# R7FA8M1AH register map
Vendor: Renesas; Series: RA8; File version: 1.2
CPU: CM85 r0p0, little endian, MPU, FPU, VTOR, 4 interrupt priority bits
Registers are 32-bit, read-write, reset 0x0 unless marked. A register's access mark holds for its fields unless they carry their own. Offsets are from the block's base; [hi:lo] are bit positions.

## FACI — Flash Application Command Interface
Base 0x4011E000
Same registers: FACI_NS 0x5011E000
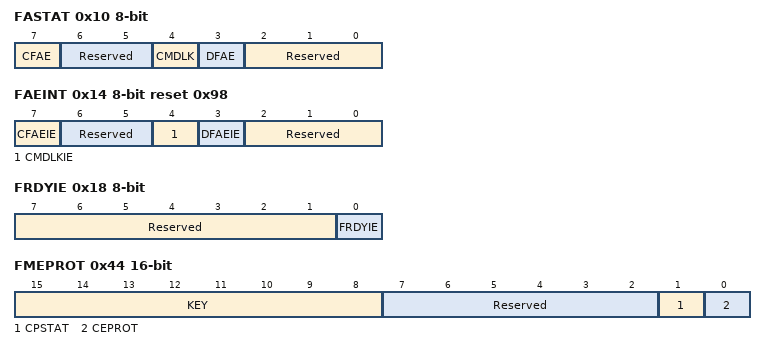
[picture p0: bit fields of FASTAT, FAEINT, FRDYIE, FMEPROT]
0x10 FASTAT 8-bit — Flash Access Status Register
  [7] CFAE write-0-clears read-modifies — Code Flash Access Error
    0=No code flash access error has occurred; 1=Code flash access error has occurred
  [6:5] Reserved — These bits are read as 00. The write value should be 00.
  [4] CMDLK ro — Command Lock
    0=Flash sequencer is not in "Command Lock" state; 1=Flash sequencer is in "Command Lock" state
  [3] DFAE write-0-clears read-modifies — Data Flash Access Error
    0=No data flash access error has occurred; 1=Data flash access error has occurred
  [2:0] Reserved — These bits are read as 000. The write value should be 000.
0x14 FAEINT 8-bit reset 0x98 — Flash Access Error Interrupt Enable Register
  [7] CFAEIE — Code Flash Access Error Interrupt Enable
    0=Does not generate "intflerr" interrupt request when CFAE = "1"; 1=Generates "intflerr" interrupt request when CFAE = "1"
  [6:5] Reserved — These bits are read as 00. The write value should be 00.
  [4] CMDLKIE — Command Lock Interrupt Enable
    0=Does not generate "intflerr" interrupt request when CMDLK = "1"; 1=Generates "intflerr" interrupt request when CMDLK = "1"
  [3] DFAEIE — Data Flash Access Error Interrupt Enable
    0=Does not generate "intflerr" interrupt request when DFAE = "1"; 1=Generates "intflerr" interrupt request when DFAE = "1"
  [2:0] Reserved — These bits are read as 000. The write value should be 000.
0x18 FRDYIE 8-bit — Flash Ready Interrupt Enable Register
  [7:1] Reserved — These bits are read as 0000000. The write value should be 0000000.
  [0] FRDYIE — FRDY Interrupt Enable
    0=Does not generate "intflend" interrupt request when FRDY is changed from "0" to "1"; 1=Generates "intflend" interrupt request when FRDY is changed from "0" to "1"
0x30 FSADDR — FACI Command Start Address Register
  [31:0] FSADDR — Start Address of Flash Sequencer Command Target AreaThese bits can be written when FRDY bit of FSTATR register is "1". Writing to these bits in FRDY = "0" is ignored.
    other=others (Specifies start address for each command processing.)
0x34 FEADDR — FACI Command End Address Register
  [31:0] FEADDR — End Address of Flash Sequencer Command Target AreaSpecifies end address of target area in "Blank Check" command.These bits can be written when FRDY bit of FSTATR register is "1". Writing to these bits in FRDY = "0" is ignored.
0x44 FMEPROT 16-bit — Flash P/E Mode Entry Protection Register
  [15:8] KEY wo — Key CodeThese bits enable or disable CEPROT bit modification. The data written to these bits are not stored.
    217=Writing to the other bits in this register is enabled; other=others (Writing to the other bits in this register is disabled.)
  [7:2] Reserved — These bits are read as 000000. The write value should be 000000.
  [1] CPSTAT ro — fac_cpstat pin Monitor
    0=Protection by CEPROT bit is enabled. ("fac_cpstat" pin = "0"); 1=Protection by CEPROT bit is disabled. ("fac_cpstat" pin = "1")
  [0] CEPROT — Code Flash P/E Mode Entry Protection
    0=FENTRYC bit is not protected; 1=FENTRYC bit is protected
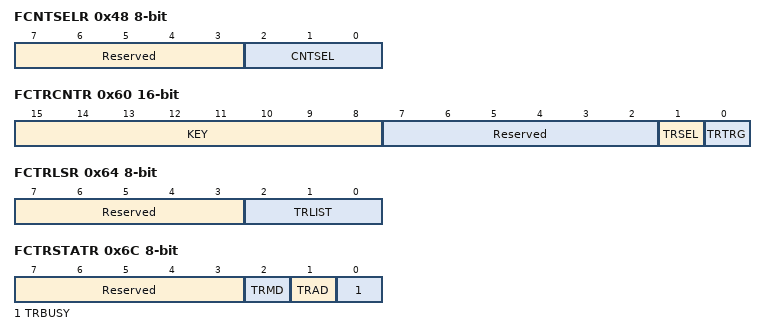
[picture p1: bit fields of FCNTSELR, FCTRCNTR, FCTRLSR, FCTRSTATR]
0x48 FCNTSELR 8-bit — Flash Counter Select Register
  [7:3] Reserved — These bits are read as 00000. The write value should be 00000.
  [2:0] CNTSEL — Counter Select
0x4C FCNTDATAR0 ro — Flash Counter Data Register 0
  [31:0] CNTRDAT — Counter Read Data
0x50 FCNTDATAR1 ro — Flash Counter Data Register 1
  [31:0] CNTRDAT — Counter Read Data
0x60 FCTRCNTR 16-bit — Flash Configuration Update Transfer Control Register
  [15:8] KEY wo — Key Code
  [7:2] Reserved — These bits are read as 000000. The write value should be 000000.
  [1] TRSEL — Transfer Information Select
  [0] TRTRG — Transfer Start Trigger
0x64 FCTRLSR 8-bit — Flash Configuration Update Transfer List Select Register
  [7:3] Reserved — These bits are read as 00000. The write value should be 00000.
  [2:0] TRLIST — Configuration Update Transfer List
0x68 FCTRADDR — Flash Configuration Update Transfer Address Register
  [31:0] CTRA — Configuration Update Transfer Source Address
0x6C FCTRSTATR 8-bit ro — Flash Configuration Update Transfer Status Register
  [7:3] Reserved — These bits are read as 00000.
  [2] TRMD — Transfer Mode Setting Status
  [1] TRAD — Transfer Address Setting Status
  [0] TRBUSY — Transfer Busy Status
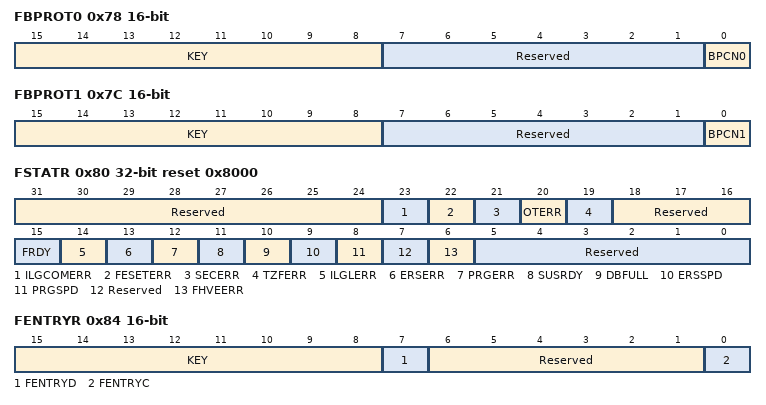
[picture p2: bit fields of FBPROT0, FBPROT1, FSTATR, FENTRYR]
0x78 FBPROT0 16-bit — Flash Block Protection
  [15:8] KEY wo — Key CodeThese bits enable or disable BPCN0 bit modification. The data written to these bits are not stored.
    120=Writing to the other bits in this register is enabled; other=others (Writing to the other bits in this register is disabled.)
  [7:1] Reserved — These bits are read as 0000000. The write value should be 0000000.
  [0] BPCN0 — Block Protection for non-secure CancelDisables block protect for non-secure function
    0=User area is protected; 1=User area is not protected
0x7C FBPROT1 16-bit — Flash Block Protection for secure Register
  [15:8] KEY wo — Key CodeThese bits enable or disable BPCN1 bit modification. The data written to these bits are not stored.
    177=Writing to the other bits in this register is enabled; other=others (Writing to the other bits in this register is disabled.)
  [7:1] Reserved — These bits are read as 0000000. The write value should be 0000000.
  [0] BPCN1 — Block Protection for secure CancelDisables block protection for secure
    0=User area is protected; 1=User area is not protected
0x80 FSTATR ro reset 0x8000 — Flash Status Register
  [31:24] Reserved — These bits are read as 00000000.
  [23] ILGCOMERR — Illegal Command ErrorWhen this bit is "1", flash sequencer enters "Command Lock" state.
  [22] FESETERR — FENTRY Setting ErrorWhen this bit is "1", flash sequencer enters "Command Lock" state.
  [21] SECERR — Security ErrorWhen this bit is "1", flash sequencer enters "Command Lock" state.
  [20] OTERR — Other ErrorWhen this bit is "1", flash sequencer enters "Command Lock" state.
  [19] TZFERR — TrustZone Filter ErrorWhen this bit is "1", flash sequencer enters "Command Lock" state.
  [18:16] Reserved — These bits are read as 000.
  [15] FRDY — Flash Ready
    0="Program", "DMA Program", "Erase", "Program" or "Erase" command suspension, "Forced Stop", "Blank Check", "Config Program", "Config Clear", "Lock Bit Program", "Lock Bit Read", or "OTP Program" is processing; 1=None of the above is in progress
  [14] ILGLERR — Illegal Command Error
    0=Flash sequencer has not detected any illegal command or illegal flash memory access; 1=Flash sequencer has detected an illegal command or illegal flash memory access
  [13] ERSERR — Erasure Error
    0=Erasure processing has been completed successfully; 1=An error has occurred during erasure
  [12] PRGERR — Programming Error
    0=Programming has been completed successfully; 1=An error has occurred during programming
  [11] SUSRDY — Suspend Ready
    0=Flash sequencer cannot accept "Program/Erase Suspend" command; 1=Flash sequencer can accept "Program/Erase Suspend" command
  [10] DBFULL — Data Buffer Full
    0=Data Buffer is not full
  [9] ERSSPD — Erasure-Suspended Status
    0=Flash sequencer is in status other than the below mentioned; 1=Flash sequencer is in erasure suspension process or erasure-suspended status
  [8] PRGSPD — Programming-Suspended Status
    0=Flash sequencer is in status other than the below mentioned; 1=Flash sequencer is in programming suspension process or programming-suspended status
  [7] Reserved — This bit is read as 0.
  [6] FHVEERR — "fhve" Error
    0=No error has been detected; 1=An error has been detected
  [5:0] Reserved — These bits are read as 000000.
0x84 FENTRYR 16-bit — Flash P/E Mode Entry Register
  [15:8] KEY wo — KEY Code
    170=Writing to the other bits in this register is enabled; other=others (Writing to the other bits in this register is disabled.)
  [7] FENTRYD — Data Flash P/E Mode EntryThese bits can be written when FRDY bit in FSTATR register is "1". Writing to this bit in FRDY = "0" is ignored.Writing to these bits is enabled only when this register is accessed in 16-bit size and H'AA is written to KEY bits.
    0=Data flash is in "Read Mode"; 1=Data flash is in "P/E Mode"
  [6:1] Reserved — These bits are read as 000000. The write value should be 000000.
  [0] FENTRYC — Code Flash P/E Mode EntryThese bits can be written when FRDY bit in FSTATR register is "1". Writing to this bit in FRDY = "0" is ignored.Writing to these bits is enabled only when this register is accessed in 16-bit size and H'AA is written to KEY bits
    0=Code flash is in "Read Mode"; 1=Code flash is in "P/E Mode"
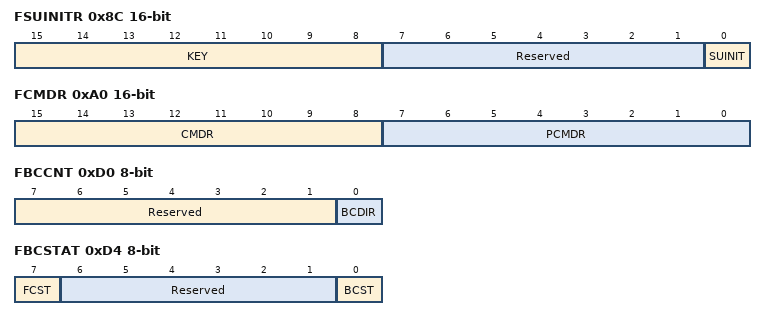
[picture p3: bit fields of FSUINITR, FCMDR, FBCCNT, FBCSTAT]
0x8C FSUINITR 16-bit — Flash Sequencer Set-Up Initialization Register
  [15:8] KEY wo — KEY Code
    45=Writing to the other bits in this register is enabled; other=others (Writing to the other bits in this register is disabled.)
  [7:1] Reserved — These bits are read as 0000000. The write value should be 0000000.
  [0] SUINIT — Set-up InitializationThis bit can be written when FRDY bit of FSTATR register is "1". Writing to this bit in FRDY = "0" is ignored.Writing to these bits is enabled only when this register is accessed in 16-bit size and H'2D is written to KEY bits.
    0=Set-up registers keep its' value; 1=Set-up registers are initialized
0xA0 FCMDR 16-bit ro — FACI Command Register
  [15:8] CMDR — Command Register
    other=others (These bits store the latest command accepted by FACI.)
  [7:0] PCMDR — Previous Command Register
    other=others (These bits store previous command accepted by FACI.)
0xD0 FBCCNT 8-bit — Data Flash Blank Check Control Register
  [7:1] Reserved — These bits are read as 0000000. The write value should be 0000000.
  [0] BCDIR — Blank Check Direction
    0=Blank check is executed from smaller address to larger address. (Incremental mode); 1=Blank check is executed from larger address to smaller address. (Decremental mode)
0xD4 FBCSTAT 8-bit ro — Data Flash Blank Check Control Register
  [7] FCST — Fill Check Status Bit
    0=The target area is filled with 0s and/or 1s; 1=The target area is blank. (not programmed)
  [6:1] Reserved — These bits are read as 000000.
  [0] BCST — Blank Check Status Bit
    0=The target area is erased (blank); 1=The target area is filled with 0s and/or 1s
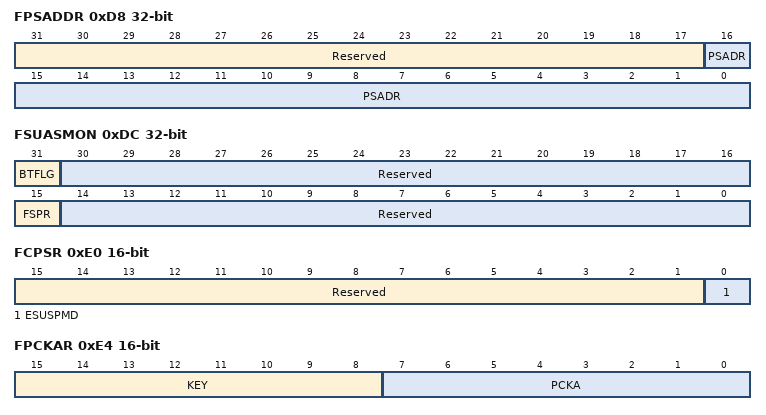
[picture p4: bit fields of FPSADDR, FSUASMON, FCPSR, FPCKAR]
0xD8 FPSADDR ro — Data Flash Programming Start Address Register
  [31:17] Reserved — These bits are read as 000000000000000.
  [16:0] PSADR — Programmed Area Start AddressNOTE: Indicates address of the first programmed data which is found in "Blank Check" command execution.
0xDC FSUASMON ro reset not defined — Flash Start-Up Area Select Monitor Register
  [31] BTFLG — Flag of Start-Up area select for Boot Swap
    0=The start-up area is the alternate area (sector 1); 1=The start-up area is the default area (sector 0)
  [30:16] Reserved — These bits are read as 000000000000000.
  [15] FSPR — Protection Flag of programing the Access Window, Boot Flag and Temporary Boot Swap Control and "Config Clear" command execution
    0=Protected state; 1=Non-protected state
  [14:0] Reserved — These bits are read as 000000000000000.
0xE0 FCPSR 16-bit — Flash Sequencer Processing Switching Register
  [15:1] Reserved — These bits are read as 000000000000000. The write value should be 000000000000000.
  [0] ESUSPMD — Erasure-Suspended Mode
    0=Suspension-priority mode; 1=Erasure-priority mode
0xE4 FPCKAR 16-bit — Flash Sequencer Processing Clock Notification Register
  [15:8] KEY wo — KEY Code
    30=Writing to the other bits in this register is enabled; other=others (Writing to the other bits in this register is disabled.)
  [7:0] PCKA — Flash Sequencer Processing Clock FrequencyThese bits can be written when FRDY bit in FSTATR register is "1". Writing to this bit in FRDY = "0" is ignored.Writing to these bits is enabled only when this register is accessed in 16-bit size and H'1E is written to KEY bits.
    other=others (Notifies operating frequency of clkf.)
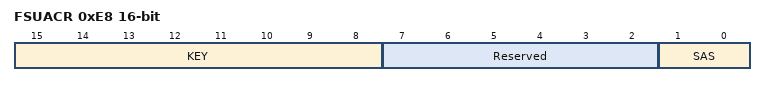
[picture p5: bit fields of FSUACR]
0xE8 FSUACR 16-bit — Flash Start-Up Area Control Register
  [15:8] KEY wo — KEY CodeThese bits enable or disable SAS bits modification. The data written to these bits are not stored.
    102=Writing to the other bits in this register is enabled; other=others (Writing to the other bits in this register is disabled.)
  [7:2] Reserved — These bits are read as 000000. The write value should be 000000.
  [1:0] SAS — Start Up Area SelectThese bits can be written when FRDY bit in FSTATR register is "1". Writing to this bit in FRDY = "0" is ignored.Writing to these bits is enabled only when this register is accessed in 16-bit size and H'66 is written to KEY bits.
    2=The start-up area is temporarily switched to the default area (sector 0) regardless of the BTFLG bit. When a reset is generated after setting, the start-up area is selected according to the BTFLG bit.; 3=The start-up area is temporarily switched to the alternate area (sector 1) regardless of the BTFLG bit. When a reset is generated after setting, the start-up area is selected according to the BTFLG bit.; other=others (The start-up area is selected according to the start-up area setting of the configuration area (BTFLG bit).)
